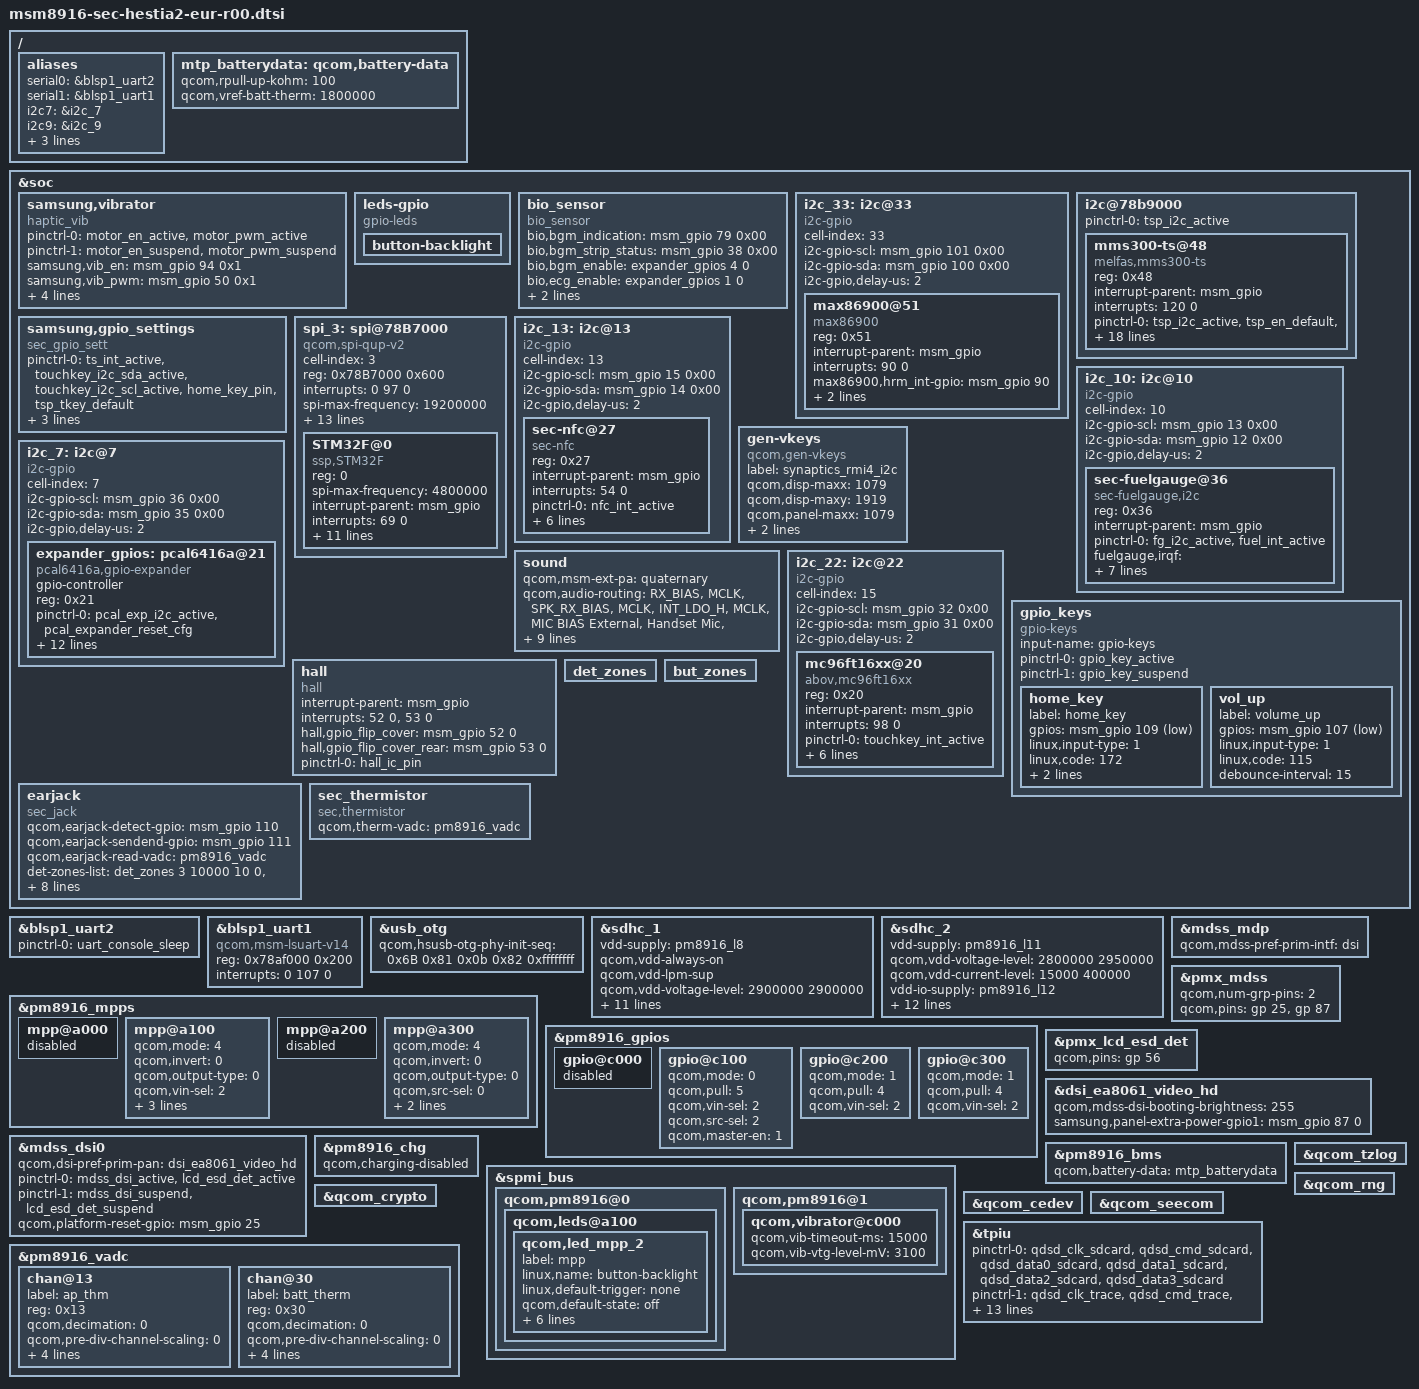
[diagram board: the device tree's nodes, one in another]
/* Copyright (c) 2014, The Linux Foundation. All rights reserved.
 *
 * This program is free software; you can redistribute it and/or modify
 * it under the terms of the GNU General Public License version 2 and
 * only version 2 as published by the Free Software Foundation.
 *
 * This program is distributed in the hope that it will be useful,
 * but WITHOUT ANY WARRANTY; without even the implied warranty of
 * MERCHANTABILITY or FITNESS FOR A PARTICULAR PURPOSE.  See the
 * GNU General Public License for more details.
 */

#include "msm8916.dtsi"
#include "msm8916-pinctrl-sec-hestia2-eur-r00.dtsi"
#include "msm8916-camera-sensor-hestia2-r00.dtsi"
#include "msm8916-sec-hestia2-eur-battery-r00.dtsi"
#include "../../../../../../drivers/video/msm/mdss/samsung/EA8061V_AMS497EE01/dsi_panel_EA8061V_AMS497EE01_hd_octa_video.dtsi"
#include "msm8916-max77849-hestia2.dtsi"


/ {
	aliases {
		serial0 = &blsp1_uart2;
		serial1 = &blsp1_uart1;
		/*i2c-gpio bus_id*/
		i2c7 = &i2c_7;
		i2c9 = &i2c_9;
		i2c13 = &i2c_13;
		i2c33 = &i2c_33;
		spi3 = &spi_3;
	};
};

&soc {

	samsung,vibrator {
		compatible = "haptic_vib";
		pinctrl-names = "tlmm_motor_active","tlmm_motor_suspend";
		pinctrl-0 = <&motor_en_active &motor_pwm_active>;
		pinctrl-1 = <&motor_en_suspend &motor_pwm_suspend>;
		samsung,vib_en = <&msm_gpio 94 0x1>;
		samsung,vib_pwm = <&msm_gpio 50 0x1>;
		samsung,vib_model = <1>;
		samsung,is_pmic_vib_pwm = <0>;
		samsung,pwm_period_us = <40>;
		samsung,duty_us = <36>;
		status = "ok";
	};

	leds-gpio{
		compatible = "gpio-leds";
		button-backlight{
			/*gpios = <&msm_gpio 97 0>;*/
			status = "ok";
		};
	};

	bio_sensor {
		compatible = "bio_sensor";
		bio,bgm_indication = <&msm_gpio 79 0x00>;
		bio,bgm_strip_status = <&msm_gpio 38 0x00>;
		bio,bgm_enable = <&expander_gpios 4 0>;
		bio,ecg_enable = <&expander_gpios 1 0>;
		bio,ecg_boot0 = <&expander_gpios 0 0>;
		bio,ecg_reset = <&expander_gpios 2 0>;
		status = "ok";
	};

	i2c_33:i2c@33{
		cell-index = <33>;
		compatible = "i2c-gpio";
		i2c-gpio-scl = <&msm_gpio 101 0x00>;
		i2c-gpio-sda = <&msm_gpio 100 0x00>;
		i2c-gpio,delay-us = <2>;
		#address-cells = <1>;
		#size-cells = <0>;
		max86900@51 {
			compatible = "max86900";
			reg = <0x51>;
			interrupt-parent = <&msm_gpio>;
			interrupts = <90 0>;
			max86900,hrm_int-gpio = <&msm_gpio 90 0x00>;
			max86900,led_en-gpio = <&expander_gpios 5 0>;
			max86900,hrm_vdd-gpio = <&expander_gpios 6 0>;
		};
	};

	i2c@78b9000 {
		status = "okay";
		pinctrl-names = "i2c_default";
		pinctrl-0 = <&tsp_i2c_active>;
		mms300-ts@48 {
			compatible = "melfas,mms300-ts";
			reg = <0x48>; /*slave address*/
			interrupt-parent = <&msm_gpio>;
			interrupts = <120 0>; /* Touch int gpio */
			pinctrl-names = "tsp_gpio_default", "tsp_firmup_start", "tsp_firmup_end";
			pinctrl-0 = <&tsp_i2c_active &tsp_en_default &tsp_irq_default>;
			pinctrl-1 = <&tsp_i2c_default>;
			pinctrl-2 = <&tsp_i2c_active>;
			melfas,tsppwr_en = <&msm_gpio 73 0x1>;
			melfas,irq-gpio = <&msm_gpio 120 0x00>; /*TSP IRQ GPIO */
			melfas,i2c-pull-up = <1>;
			melfas,sda-gpio = <&msm_gpio 18 0x00>;
			melfas,scl-gpio = <&msm_gpio 19 0x00>;
			melfas,update-func = <1 0>; /* ISP ISC */
			melfas,num_x = <26>; /*num of x-node*/
			melfas,num_y = <14>; /*num of y node*/
			melfas,max_x = <720>; /*max x*/
			melfas,max_y = <1280>; /*max y*/
			melfas,temp = <&msm_gpio 73 0x00>;
			melfas,panel-coords = <0 0 0 0>;
			melfas,config_fw_version = "melfas mms300";
			melfas,pname = "MSM8916_A5C"; /*MSM8916 KELOS*/
			melfas,gpio_seperated = <1>;
		};
	};

	samsung,gpio_settings{
		compatible = "sec_gpio_sett";
		pinctrl-names = "sec_gpio_active","sec_gpio_suspend";
		pinctrl-0 = <&ts_int_active &touchkey_i2c_sda_active &touchkey_i2c_scl_active &home_key_pin &tsp_tkey_default>;
		pinctrl-1 = <&ts_int_suspend &tsp_tkey_sleep &touchkey_i2c_sda_suspend &touchkey_i2c_scl_suspend>;
	};

	spi_3: spi@78B7000 {  /* BLSP1 QUP3 */
		compatible = "qcom,spi-qup-v2";
		cell-index = <3>;
		#address-cells = <1>;
		#size-cells = <0>;
		reg = <0x78B7000 0x600>;
		reg-names = "spi_physical";
		interrupts = <0 97 0>;
		interrupt-names = "spi_irq";
		spi-max-frequency = <19200000>;
		clocks = <&clock_gcc clk_gcc_blsp1_ahb_clk>,
			 <&clock_gcc clk_gcc_blsp1_qup3_spi_apps_clk>;
		clock-names = "iface_clk", "core_clk";
		pinctrl-names = "default", "sleep";
		pinctrl-0 = <&spi3_default>;
		pinctrl-1 = <&spi3_sleep>;

		qcom,gpio-mosi = <&msm_gpio 8 0x00>;
		qcom,gpio-miso = <&msm_gpio 9 0x00>;
		qcom,gpio-cs0  = <&msm_gpio 10 0x00>;
		qcom,gpio-clk  = <&msm_gpio 11 0x00>;

		qcom,infinite-mode = <0>;
		qcom,use-pinctrl;
		qcom,ver-reg-exists;
		qcom,master-id = <86>;
		qcom,rt-priority;
		status = "ok";
		STM32F@0 {
			compatible = "ssp,STM32F";
			reg = <0>;
			spi-max-frequency = <4800000>;
			interrupt-parent = <&msm_gpio>;
			interrupts = <69 0>;
			pinctrl-names = "mcu_active", "mcu_suspend";
			pinctrl-0 = <&mcu_default>;
			pinctrl-1 = <&mcu_sleep>;
			ssp,mcu_int1-gpio = <&msm_gpio 69 0x00>;
			ssp,mcu_int2-gpio = <&msm_gpio 113 0x00>;
			ssp,ap_int-gpio = <&msm_gpio 20 0x00>;
			ssp,rst-gpio = <&msm_gpio 21 0x00>;
			ssp,acc-position = <3>;
			ssp,mag-position = <3>;
			ssp,ap-rev = <10>;
			ssp,mag-supply-name = "8916_l17";
			qcom,temphumidity_sensor-vadc = <&pm8916_vadc>;
		};
	};

	i2c_13:i2c@13 {
		cell-index = <13>;
		compatible = "i2c-gpio";
		i2c-gpio-scl = <&msm_gpio 15 0x00>;
		i2c-gpio-sda = <&msm_gpio 14 0x00>;
		i2c-gpio,delay-us = <2>;
		#address-cells = <1>;
		#size-cells = <0>;

		sec-nfc@27 {
			compatible = "sec-nfc";
			reg = <0x27>;
			interrupt-parent = <&msm_gpio>;
			interrupts = <54 0>;
			pinctrl-names = "nfc_active","nfc_suspend";
			pinctrl-0 = <&nfc_int_active>;
			pinctrl-1 = <&nfc_int_suspend>;
			sec-nfc,firm-gpio = <&expander_gpios 15 0>;
			sec-nfc,ven-gpio = <&expander_gpios 14 0>;
			sec-nfc,irq-gpio = <&msm_gpio 54 0x00>;
			nfc_ldo-supply = <&pm8916_l14>;
			clocks = <&clock_rpm clk_bb_clk2_pin>;
			clock-names = "nfc_clock";
		};
	};

	i2c_10:i2c@10 {
		cell-index = <10>;
		compatible = "i2c-gpio";
		i2c-gpio-scl = <&msm_gpio 13 0x00>;
		i2c-gpio-sda = <&msm_gpio 12 0x00>;
		i2c-gpio,delay-us = <2>;
		#address-cells = <1>;
		#size-cells = <0>;

		sec-fuelgauge@36{
			compatible = "sec-fuelgauge,i2c";
			reg = <0x36>;
			interrupt-parent = <&msm_gpio>;
			pinctrl-names = "default";
			pinctrl-0 = <&fg_i2c_active &fuel_int_active>;
			fuelgauge,irqf = "IRQF_TRIGGER_FALLING + IRQF_ONESHOT + IRQF_NO_SUSPEND";
			fuelgauge,fuel_int = <&msm_gpio 121 0x1>;
			fuelgauge,capacity_max = <1000>;
			fuelgauge,capacity_max_margin = <50>;
			fuelgauge,capacity_min = <0>;
			fuelgauge,capacity_calculation_type = <0x17>;
			fuelgauge,fuel_alert_soc = <1>;
		};
	};

	gen-vkeys {
		compatible = "qcom,gen-vkeys";
		label = "synaptics_rmi4_i2c";
		qcom,disp-maxx = <1079>;
		qcom,disp-maxy = <1919>;
		qcom,panel-maxx = <1079>;
		qcom,panel-maxy = <2084>;
		qcom,key-codes = <158 139 172 217>;
	};

	i2c_7: i2c@7 {
		cell-index = <7>;
		compatible = "i2c-gpio";
		/*notice, change how to get gpio value*/
		i2c-gpio-scl = <&msm_gpio 36 0x00>;
		i2c-gpio-sda = <&msm_gpio 35 0x00>;
		i2c-gpio,delay-us = <2>;
		#address-cells = <1>;
		#size-cells = <0>;


		expander_gpios: pcal6416a@21 {
			compatible = "pcal6416a,gpio-expander";
			gpio-controller;
			#gpio-cells = <2>;
			reg = <0x21>;
			pinctrl-names = "expander_active","expander_suspend";
			pinctrl-0 = <&pcal_exp_i2c_active &pcal_expander_reset_cfg>;
			pinctrl-1 = <&pcal_exp_i2c_suspend &pcal_expander_reset_cfg>;
			pcal6416a,gpio_start = <300>;
			pcal6416a,ngpio = <16>;
			pcal6416a,sda-gpio = <&msm_gpio 35 0>;
			pcal6416a,scl-gpio = <&msm_gpio 36 0>;
			pcal6416a,reset-gpio = <&msm_gpio 55 0>;
			pcal6416a,supply-name = "8916_l15";
			pcal6416a,support_initialize = <1>;
			/* config, 15 ~ 0, 1bit configure[1:input, 0:output]*/
			pcal6416a,config = <0x2008>;	/* 0010 0000 0000 1000 */
			/* data_out, 15 ~ 0, 1bit configure[1:high, 0:low]*/
			pcal6416a,data_out = <0x4484>;  /* 0000 0100 1000 0100  */
			/* pull_reg, 31 ~ 0, 2bit configure[00:no_pull, 01:pull_down, 10:pull_up, 11:not used]*/
			pcal6416a,pull_reg = <0x00000000>; /* 00 00 00 00 / 00 00 00 00 /  00 00 00 00 / 00 00 00 00 */
		};
    };

	/* Over-riding model specific changes */
	sound {
		qcom,msm-ext-pa = "quaternary";
		qcom,audio-routing =
			"RX_BIAS", "MCLK",
			"SPK_RX_BIAS", "MCLK",
			"INT_LDO_H", "MCLK",
			"MIC BIAS External", "Handset Mic",
			"MIC BIAS External", "Secondary Mic",
			"AMIC1", "MIC BIAS External",
			"AMIC2", "Headset Mic",
			"AMIC3", "MIC BIAS External";
		pinctrl-names = "cdc_lines_act",
				"cdc_lines_sus",
				"cdc_lines_quat_ext_act",
				"cdc_lines_quat_ext_sus";
		pinctrl-0 = <&cdc_pdm_lines_act>;
		pinctrl-1 = <&cdc_pdm_lines_sus>;
		pinctrl-2 = <&cdc_pdm_lines_act &ext_cdc_tlmm_lines_act>;
		pinctrl-3 = <&cdc_pdm_lines_sus &ext_cdc_tlmm_lines_sus>;
	};
	i2c_22: i2c@22 {
		cell-index = <15>;
		compatible = "i2c-gpio";
		i2c-gpio-scl = <&msm_gpio 32 0x00>;
		i2c-gpio-sda = <&msm_gpio 31 0x00>;
		i2c-gpio,delay-us = <2>;
		#address-cells = <1>;
		#size-cells = <0>;
		mc96ft16xx@20{
			compatible = "abov,mc96ft16xx";
			reg = <0x20>;
			interrupt-parent = <&msm_gpio>;
			interrupts = <98 0>;
			pinctrl-names = "touchkey_int_gpio_active", "touchkey_int_gpio_suspend";
			pinctrl-0 = <&touchkey_int_active>;
			pinctrl-1 = <&touchkey_int_suspend>;
			abov,sda-gpio = <&msm_gpio 31 0>;
			abov,scl-gpio = <&msm_gpio 32 0>;
			abov,irq-gpio = <&msm_gpio 98 0>;
			/*abov,tkey_en-gpio = <&msm_gpio 86 0>;*/
			abov,tkey_led_en-gpio = <&msm_gpio 97 0>;
			/*vddo-supply = <&pm8916_l6>;*/
			abov,gpio_seperated = <1>;
		};
         };

};

&blsp1_uart2 {
	status = "ok";
	pinctrl-names = "default";
	pinctrl-0 = <&uart_console_sleep>;
};

&soc {
	gpio_keys {
		compatible = "gpio-keys";
		input-name = "gpio-keys";
		pinctrl-names = "tlmm_gpio_key_active","tlmm_gpio_key_suspend";
		pinctrl-0 = <&gpio_key_active>;
		pinctrl-1 = <&gpio_key_suspend>;

		home_key {
			label = "home_key";
			gpios = <&msm_gpio 109 0x1>;
			linux,input-type = <1>;
			linux,code = <172>;
			gpio-key,wakeup;
			debounce-interval = <15>;
		};
		vol_up {
			label = "volume_up";
			gpios = <&msm_gpio 107 0x1>;
			linux,input-type = <1>;
			linux,code = <115>;
			debounce-interval = <15>;
		};
	};

	hall {
		status = "okay";
		compatible = "hall";
		interrupt-parent = <&msm_gpio>;
		interrupts = <52 0>, <53 0>;
		hall,gpio_flip_cover = <&msm_gpio 52 0>;
		hall,gpio_flip_cover_rear = <&msm_gpio 53 0>;
		pinctrl-names = "pmx_hall_ic_pin";
		pinctrl-0 = <&hall_ic_pin>;

	};

	det_zones: det_zones {
		#list-det-cells = <4>;
	};

	but_zones: but_zones {
		#list-but-cells = <3>;
	};

	earjack {
		compatible = "sec_jack";
		qcom,earjack-detect-gpio = <&msm_gpio 110 0x0>;
		qcom,earjack-sendend-gpio = <&msm_gpio 111 0x0>;
		qcom,earjack-read-vadc = <&pm8916_vadc>;

		det-zones-list = <&det_zones 3 10000 10 0>,
				 <&det_zones 975 10000 10 0>,
				 <&det_zones 976 10000 10 1>,
				 <&det_zones 9999 10000 10 1>;
		but-zones-list = <&but_zones 0 0 317>,
				 <&but_zones 1 318 447>,
				 <&but_zones 2 448 975>;
		mpp-channel-scaling = <2 1 1>;
		pinctrl-names = "earjack_gpio_active","earjack_gpio_suspend";
		pinctrl-0 = <&earjack_det_act &earjack_switch_act>;
		pinctrl-1 = <&earjack_det_sus &earjack_switch_sus>;
	};

	sec_thermistor {
		compatible = "sec,thermistor";
		qcom,therm-vadc = <&pm8916_vadc>;
	};
};

&blsp1_uart1 {
	compatible = "qcom,msm-lsuart-v14";
	reg = <0x78af000 0x200>;
	interrupts = <0 107 0>;
	status = "ok";
};

&usb_otg {
	qcom,hsusb-otg-phy-init-seq =
					<0x6B 0x81 0x0b 0x82 0xffffffff>;
};

&sdhc_1 {
	vdd-supply = <&pm8916_l8>;
	qcom,vdd-always-on;
	qcom,vdd-lpm-sup;
	qcom,vdd-voltage-level = <2900000 2900000>;
	qcom,vdd-current-level = <200 400000>;

	vdd-io-supply = <&pm8916_l5>;
	qcom,vdd-io-always-on;
	qcom,vdd-io-lpm-sup;
	qcom,vdd-io-voltage-level = <1800000 1800000>;
	qcom,vdd-io-current-level = <200 60000>;

	pinctrl-names = "active", "sleep";
	pinctrl-0 = <&sdc1_clk_on &sdc1_cmd_on &sdc1_data_on>;
	pinctrl-1 = <&sdc1_clk_off &sdc1_cmd_off &sdc1_data_off>;

	qcom,nonremovable;

	status = "ok";
};

&sdhc_2 {
	vdd-supply = <&pm8916_l11>;
	qcom,vdd-voltage-level = <2800000 2950000>;
	qcom,vdd-current-level = <15000 400000>;

	vdd-io-supply = <&pm8916_l12>;
	qcom,vdd-io-voltage-level = <1800000 2950000>;
	qcom,vdd-io-current-level = <200 50000>;

	pinctrl-names = "active", "sleep";
	pinctrl-0 = <&sdc2_clk_on &sdc2_cmd_on &sdc2_data_on &sdc2_cd_on>;
	pinctrl-1 = <&sdc2_clk_off &sdc2_cmd_off &sdc2_data_off &sdc2_cd_off>;

	#address-cells = <0>;
	interrupt-parent = <&sdhc_2>;
	interrupts = <0 1 2>;
	#interrupt-cells = <1>;
	interrupt-map-mask = <0xffffffff>;
	interrupt-map = <0 &intc 0 125 0
			1 &intc 0 221 0
			2 &msm_gpio 60 0>;
	interrupt-names = "hc_irq", "pwr_irq", "status_irq";
	cd-gpios = <&msm_gpio 60 0x1>;

	status = "ok";
};

&pm8916_mpps {
	mpp@a000 { /* MPP 1 */
		/* VDD_PX */
		status = "disabled";
	};

	mpp@a100 { /* MPP 2 */
		status = "ok";
		qcom,mode = <4>; // AIN input
		qcom,invert = <0>; //No Invert
		qcom,output-type = <0>; //CMOS
		qcom,vin-sel = <2>; //PM8971_S3 1.8v
		qcom,src-sel = <0>; //MPP Constant
		qcom,ain-route = <1>; // QPNP_PIN_AIN_AMUX_CH6 = 1 for MPP2
		qcom,master-en = <1>; // Function constant
	};

	mpp@a200 { /* MPP 3 */
		/* VREF DAC */
		status = "disabled";
	};

	mpp@a300 { /* MPP 4 */
		status = "ok";
		qcom,mode = <4>; // AIN input
		qcom,invert = <0>; //No Invert
		qcom,output-type = <0>; //CMOS
		qcom,src-sel = <0>; //MPP Constant
		qcom,ain-route = <3>; // QPNP_PIN_AIN_AMUX_CH8 = 3 for MPP4
		qcom,master-en = <1>; // Function constant
	};
};

&pm8916_gpios {
	gpio@c000 { /* GPIO 1 */
		/* Battery UICC Alarm */
		status = "disabled";
	};

	gpio@c100 { /* GPIO 2 */
		/* NFC_CLK_REQ */
		qcom,mode = <0>; /* QPNP_PIN_MODE_DIG_IN */
		qcom,pull = <5>; /* QPNP_PIN_PULL_NO */
		qcom,vin-sel = <2>; /* QPNP_PIN_VIN2 */
		qcom,src-sel = <2>; /* QPNP_PIN_SEL_FUNC_1 */
		qcom,master-en = <1>;
	};

	gpio@c200 { /* GPIO 3 */
		qcom,mode = <1>;        /* DIG_OUT */
		qcom,pull = <4>;        /* QPNP_PIN_PULL_DOWN */
		qcom,vin-sel = <2>;
	};

	gpio@c300 { /* GPIO 4 */
		qcom,mode = <1>;        /* DIG_OUT */
		qcom,pull = <4>;        /* QPNP_PIN_PULL_DOWN */
		qcom,vin-sel = <2>;
	};
};

&mdss_mdp {
	qcom,mdss-pref-prim-intf = "dsi";
};

&pmx_mdss {
	qcom,num-grp-pins = <2>;
	qcom,pins = <&gp 25>, <&gp 87>;
};

&pmx_lcd_esd_det {
	qcom,pins = <&gp 56>;
};

&dsi_ea8061_video_hd {
	qcom,mdss-dsi-booting-brightness = <255>;
	samsung,panel-extra-power-gpio1 = <&msm_gpio 87 0>;
};

&mdss_dsi0 {
	qcom,dsi-pref-prim-pan = <&dsi_ea8061_video_hd>;
	pinctrl-names = "mdss_default", "mdss_sleep";
	pinctrl-0 = <&mdss_dsi_active &lcd_esd_det_active>;
	pinctrl-1 = <&mdss_dsi_suspend &lcd_esd_det_suspend>;
	qcom,platform-reset-gpio = <&msm_gpio 25 0>;
};

&pm8916_chg {
	status = "ok";
	qcom,charging-disabled;
};

/ {
	mtp_batterydata: qcom,battery-data {
		qcom,rpull-up-kohm = <100>;
		qcom,vref-batt-therm = <1800000>;

		#include "batterydata-palladium.dtsi"
	};
};

&pm8916_bms {
	status = "ok";
	qcom,battery-data = <&mtp_batterydata>;
};

&spmi_bus {
	qcom,pm8916@0 {
		qcom,leds@a100 {
			status = "okay";
			qcom,led_mpp_2 {
				label = "mpp";
				linux,name = "button-backlight";
				linux,default-trigger = "none";
				qcom,default-state = "off";
				qcom,max-current = <40>;
				qcom,current-setting = <5>;
				qcom,id = <6>;
				qcom,mode = "manual";
				qcom,source-sel = <1>;
				qcom,mode-ctrl = <0x60>;
			};
		};
	};
};

&qcom_tzlog {
	status = "okay";
};

&qcom_rng {
	status = "okay";
};

&qcom_crypto {
	status = "okay";
};

&qcom_cedev {
	status = "okay";
};

&qcom_seecom {
	status = "okay";
};

/* CoreSight */
&tpiu {
      pinctrl-names = "sdcard", "trace", "swduart",
		      "swdtrc", "jtag", "spmi";
       /* NIDnT */
      pinctrl-0 = <&qdsd_clk_sdcard &qdsd_cmd_sdcard
                  &qdsd_data0_sdcard &qdsd_data1_sdcard
                  &qdsd_data2_sdcard &qdsd_data3_sdcard>;
      pinctrl-1 = <&qdsd_clk_trace &qdsd_cmd_trace
                  &qdsd_data0_trace &qdsd_data1_trace
                  &qdsd_data2_trace &qdsd_data3_trace>;
      pinctrl-2 = <&qdsd_cmd_swduart &qdsd_data0_swduart
                  &qdsd_data1_swduart &qdsd_data2_swduart
                  &qdsd_data3_swduart>;
      pinctrl-3 = <&qdsd_clk_swdtrc &qdsd_cmd_swdtrc
                  &qdsd_data0_swdtrc &qdsd_data1_swdtrc
                  &qdsd_data2_swdtrc &qdsd_data3_swdtrc>;
      pinctrl-4 = <&qdsd_cmd_jtag &qdsd_data0_jtag
                  &qdsd_data1_jtag &qdsd_data2_jtag
                  &qdsd_data3_jtag>;
      pinctrl-5 = <&qdsd_clk_spmi &qdsd_cmd_spmi
                  &qdsd_data0_spmi &qdsd_data3_spmi>;
};
&pm8916_vadc {
	chan@13 {
		label = "ap_thm";
		reg = <0x13>; // channel 19 for MPP4 , 1:1scale
		qcom,decimation = <0>;
		qcom,pre-div-channel-scaling = <0>; // 1:1scale
		qcom,calibration-type = "ratiometric";
		qcom,scale-function = <1>;
		qcom,hw-settle-time = <2>;
		qcom,fast-avg-setup = <0>;
	};

	chan@30 {
		label = "batt_therm";
		reg = <0x30>;
		qcom,decimation = <0>;
		qcom,pre-div-channel-scaling = <0>;
		qcom,calibration-type = "ratiometric";
		qcom,scale-function = <1>;
		qcom,hw-settle-time = <12>;
		qcom,fast-avg-setup = <0>;
	};
};

&spmi_bus {
	qcom,pm8916@1 {
		qcom,vibrator@c000 {
			status = "okay";
			qcom,vib-timeout-ms = <15000>;
			qcom,vib-vtg-level-mV = <3100>;
		};
	};
};
